VERSION ""

NS_ :

BS_:

BU_: MG100 ECU PCAN

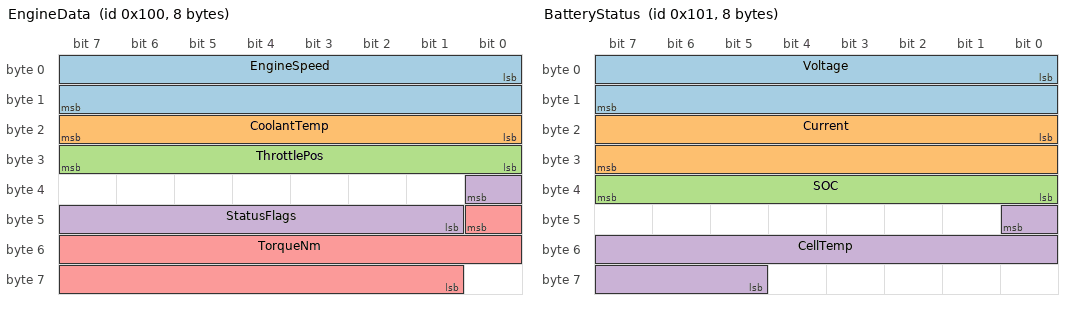
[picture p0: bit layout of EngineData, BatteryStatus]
BO_ 256 EngineData: 8 ECU
 SG_ EngineSpeed : 0|16@1+ (0.25,0) [0|16000] "rpm" PCAN
 SG_ CoolantTemp : 16|8@1+ (1,-40) [-40|215] "degC" PCAN
 SG_ ThrottlePos : 24|8@1+ (0.4,0) [0|100] "%" PCAN
 SG_ StatusFlags : 32|8@0+ (1,0) [0|255] "" PCAN
 SG_ TorqueNm : 40|16@0- (1,0) [-500|500] "Nm" PCAN

BO_ 257 BatteryStatus: 8 ECU
 SG_ Voltage : 0|16@1+ (0.01,0) [0|655.35] "V" MG100
 SG_ Current : 16|16@1- (0.1,0) [-3200|3200] "A" MG100
 SG_ SOC : 32|8@1+ (0.5,0) [0|100] "%" MG100
 SG_ CellTemp : 40|12@0+ (0.1,-40) [-40|369.5] "degC" MG100

BO_ 258 Multiplexed: 8 ECU
 SG_ MuxSelector m0 : 0|8@1+ (1,0) [0|255] "" PCAN
 SG_ SignalA M : 8|8@1+ (1,0) [0|255] "" PCAN
 SG_ SignalB m1 : 8|8@1+ (1,0) [0|255] "" PCAN

CM_ BO_ 256 "Engine data frame";
CM_ SG_ 256 StatusFlags "Bitfield of engine status";
VAL_ 257 SOC 0 "Empty" 100 "Full" ;
